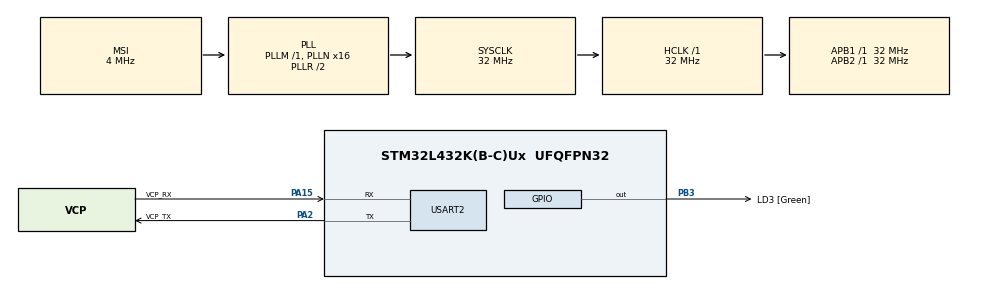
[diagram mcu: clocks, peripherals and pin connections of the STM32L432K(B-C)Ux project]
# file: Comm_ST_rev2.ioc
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Mcu.Family=STM32L4
Mcu.Name=STM32L432K(B-C)Ux
Mcu.Package=UFQFPN32
NVIC.PriorityGroup=NVIC_PRIORITYGROUP_4
NVIC.USART2_IRQn=true\:0\:0\:false\:false\:true
PA0.GPIO_Label=MCO [High speed clock in]
PA0.Signal=RCC_CK_IN
PA13\ (JTMS-SWDIO).GPIO_Label=SWDIO
PA13\ (JTMS-SWDIO).Signal=SYS_JTMS-SWDIO
PA14\ (JTCK-SWCLK).GPIO_Label=SWCLK
PA14\ (JTCK-SWCLK).Signal=SYS_JTCK-SWCLK
PA15\ (JTDI).GPIO_Label=VCP_RX
PA15\ (JTDI).Mode=Asynchronous
PA15\ (JTDI).Signal=USART2_RX
PA2.GPIO_Label=VCP_TX
PA2.Mode=Asynchronous
PA2.Signal=USART2_TX
PB3\ (JTDO-TRACESWO).GPIO_Label=LD3 [Green]
PB3\ (JTDO-TRACESWO).Signal=GPIO_Output
PC14-OSC32_IN\ (PC14).Signal=RCC_OSC32_IN
PC15-OSC32_OUT\ (PC15).Signal=RCC_OSC32_OUT
ProjectManager.HeapSize=0x200
ProjectManager.StackSize=0x400
ProjectManager.TargetToolchain=SW4STM32
RCC.AHBFreq_Value=32000000
RCC.APB1Freq_Value=32000000
RCC.APB1TimFreq_Value=32000000
RCC.APB2Freq_Value=32000000
RCC.APB2TimFreq_Value=32000000
RCC.CortexFreq_Value=32000000
RCC.HCLKFreq_Value=32000000
RCC.HSE_VALUE=8000000
RCC.HSI16_VALUE=16000000
RCC.HSI48_VALUE=48000000
RCC.HSI_VALUE=16000000
RCC.LSE_VALUE=32768
RCC.MSI_VALUE=4000000
RCC.PLLMUL=RCC_PLLMUL_4
RCC.PLLN=16
RCC.SYSCLKFreq_VALUE=32000000
RCC.SYSCLKSource=RCC_SYSCLKSOURCE_PLLCLK
RCC.VCOOutputFreq_Value=64000000
USART2.VirtualMode-Asynchronous=VM_ASYNC
USART2.WordLength=WORDLENGTH_8B
board=NUCLEO-L432KC

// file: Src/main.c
/**
  ******************************************************************************
  * File Name          : main.c
  * Description        : Main program body
  ******************************************************************************
  ** This notice applies to any and all portions of this file
  * that are not between comment pairs USER CODE BEGIN and
  * USER CODE END. Other portions of this file, whether
  * inserted by the user or by software development tools
  * are owned by their respective copyright owners.
  *
  * COPYRIGHT(c) 2018 STMicroelectronics
  *
  * Redistribution and use in source and binary forms, with or without modification,
  * are permitted provided that the following conditions are met:
  *   1. Redistributions of source code must retain the above copyright notice,
  *      this list of conditions and the following disclaimer.
  *   2. Redistributions in binary form must reproduce the above copyright notice,
  *      this list of conditions and the following disclaimer in the documentation
  *      and/or other materials provided with the distribution.
  *   3. Neither the name of STMicroelectronics nor the names of its contributors
  *      may be used to endorse or promote products derived from this software
  *      without specific prior written permission.
  *
  * THIS SOFTWARE IS PROVIDED BY THE COPYRIGHT HOLDERS AND CONTRIBUTORS "AS IS"
  * AND ANY EXPRESS OR IMPLIED WARRANTIES, INCLUDING, BUT NOT LIMITED TO, THE
  * IMPLIED WARRANTIES OF MERCHANTABILITY AND FITNESS FOR A PARTICULAR PURPOSE ARE
  * DISCLAIMED. IN NO EVENT SHALL THE COPYRIGHT HOLDER OR CONTRIBUTORS BE LIABLE
  * FOR ANY DIRECT, INDIRECT, INCIDENTAL, SPECIAL, EXEMPLARY, OR CONSEQUENTIAL
  * DAMAGES (INCLUDING, BUT NOT LIMITED TO, PROCUREMENT OF SUBSTITUTE GOODS OR
  * SERVICES; LOSS OF USE, DATA, OR PROFITS; OR BUSINESS INTERRUPTION) HOWEVER
  * CAUSED AND ON ANY THEORY OF LIABILITY, WHETHER IN CONTRACT, STRICT LIABILITY,
  * OR TORT (INCLUDING NEGLIGENCE OR OTHERWISE) ARISING IN ANY WAY OUT OF THE USE
  * OF THIS SOFTWARE, EVEN IF ADVISED OF THE POSSIBILITY OF SUCH DAMAGE.
  *
  ******************************************************************************
  */
#include "main.h"
#include "stm32l4xx_hal.h"
#include "usart.h"
#include "gpio.h"

/* USER CODE BEGIN Includes */
#include <string.h>
/* USER CODE END Includes */

/* USER CODE BEGIN PV */
/* Private variables ---------------------------------------------------------*/

/* USER CODE END PV */

void SystemClock_Config(void);

/* USER CODE BEGIN PFP */
/* Private function prototypes -----------------------------------------------*/

/* USER CODE END PFP */

/* USER CODE BEGIN 0 */

typedef struct __attribute__((packed, aligned(1))) RobotStatus{
	uint32_t id;
	char	msg[12];
} RobotStatus;
//typedef struct __attribute__((packed, aligned(1))) RobotStatus{

// } RobotStatus;
RobotStatus RS;
// scratch buffer
uint8_t Rx_char = 0;
uint8_t	Rx_index = 0;
uint8_t	is_prev_esc = 0;
uint8_t	has_started = 0;

#define MAX_SIZE_MSG sizeof(RobotStatus)
uint8_t Rx_msg[MAX_SIZE_MSG];

#define ESCAPE	0xFF
#define ESC_START	0x0F
#define ESC_END		0xF0
#define START	0x55
#define END		0xAA
// RXCallback
void RX_Parser(){
	switch(Rx_char){
		case START:	Rx_index = 0;
				is_prev_esc = 0;
				has_started = 1;
				break;
		case END:	// validate
				if(Rx_index == MAX_SIZE_MSG){
					memcpy(&RS, Rx_msg, (uint32_t)sizeof(RobotStatus));
					// Tx_Parser(&RS, sizeof(RobotStatus));
					// HAL_UART_Transmit_IT(&huart2, &RS, sizeof(RobotStatus));
				}
				is_prev_esc = 0;
				has_started = 0;
				Rx_index = 0;
				break;
		// ESCAPE
		// ESCAPE then ESCAPE
		case ESCAPE:	if(has_started){	// ignore out of context data
					if(is_prev_esc){
						Rx_msg[Rx_index] = ESCAPE;
						is_prev_esc = 0;
						Rx_index++;
					}
					else{
						is_prev_esc = 1;
					}
				}
				break;
		// ESCAPE then ESC_START
		case ESC_START:	if(has_started){
							Rx_msg[Rx_index] = (is_prev_esc) ? START : ESC_START;
							is_prev_esc = 0;
							Rx_index++;
						}
				break;
		// ESCAPE then ESC_START
		case ESC_END:	if(has_started){
							Rx_msg[Rx_index] = (is_prev_esc) ? END : ESC_END;
							is_prev_esc = 0;
							Rx_index++;
						}
				break;
		default:
				if(has_started && (is_prev_esc == 0)){
					Rx_msg[Rx_index] = Rx_char;
					Rx_index++;
					is_prev_esc = 0;
				}
	}
	HAL_UART_Receive_IT(&huart2, &Rx_char, 1);
}

#define UART_HANDLER &huart2
static void send_byte(uint8_t byte) {
	// Encapsulates the data into a packet
#ifdef PC
	int wlen = write(fd, &byte, 1);
	if (wlen != 1) {
		printf("Error from write: %d, %d\n", wlen, errno);
	}
	tcflush(fd, TCOFLUSH);
#else
	HAL_UART_Transmit(UART_HANDLER, &byte, 1, 1);
#endif
}

void Tx_Parser(uint8_t* addr, uint16_t size){
	send_byte(START);
	for(uint16_t i = 0; i < size; i++){
		switch(addr[i]){
			case START:
				send_byte(ESCAPE);
				send_byte(ESC_START);
				break;
			case END:
				send_byte(ESCAPE);
				send_byte(ESC_END);
				break;
			case ESCAPE:
				send_byte(ESCAPE);
				send_byte(ESCAPE);
				break;
			default:
				send_byte(addr[i]);
		}
	}
	send_byte(END);
}
/* USER CODE END 0 */

int main(void)
{

  /* MCU Configuration----------------------------------------------------------*/

  /* Reset of all peripherals, Initializes the Flash interface and the Systick. */
  HAL_Init();

  /* Configure the system clock */
  SystemClock_Config();

  /* Initialize all configured peripherals */
  MX_GPIO_Init();
  MX_USART2_UART_Init();

  /* USER CODE BEGIN 2 */
  HAL_UART_Receive_IT(&huart2, &Rx_char, 1);
  //RS.id = 3;
  //memcpy(RS.msg, "Test12345!@#", 12);
  //Tx_Parser(&RS, sizeof(RobotStatus));
  /* USER CODE END 2 */

  /* Infinite loop */
  while (1)
  {

  }

}

/** System Clock Configuration
*/
void SystemClock_Config(void)
{

  RCC_OscInitTypeDef RCC_OscInitStruct;
  RCC_ClkInitTypeDef RCC_ClkInitStruct;
  RCC_PeriphCLKInitTypeDef PeriphClkInit;

    /**Initializes the CPU, AHB and APB busses clocks
    */
  RCC_OscInitStruct.OscillatorType = RCC_OSCILLATORTYPE_MSI;
  RCC_OscInitStruct.MSIState = RCC_MSI_ON;
  RCC_OscInitStruct.MSICalibrationValue = 0;
  RCC_OscInitStruct.MSIClockRange = RCC_MSIRANGE_6;
  RCC_OscInitStruct.PLL.PLLState = RCC_PLL_ON;
  RCC_OscInitStruct.PLL.PLLSource = RCC_PLLSOURCE_MSI;
  RCC_OscInitStruct.PLL.PLLM = 1;
  RCC_OscInitStruct.PLL.PLLN = 16;
  RCC_OscInitStruct.PLL.PLLP = RCC_PLLP_DIV7;
  RCC_OscInitStruct.PLL.PLLQ = RCC_PLLQ_DIV2;
  RCC_OscInitStruct.PLL.PLLR = RCC_PLLR_DIV2;
  if (HAL_RCC_OscConfig(&RCC_OscInitStruct) != HAL_OK)
  {
    _Error_Handler(__FILE__, __LINE__);
  }

    /**Initializes the CPU, AHB and APB busses clocks
    */
  RCC_ClkInitStruct.ClockType = RCC_CLOCKTYPE_HCLK|RCC_CLOCKTYPE_SYSCLK
                              |RCC_CLOCKTYPE_PCLK1|RCC_CLOCKTYPE_PCLK2;
  RCC_ClkInitStruct.SYSCLKSource = RCC_SYSCLKSOURCE_PLLCLK;
  RCC_ClkInitStruct.AHBCLKDivider = RCC_SYSCLK_DIV1;
  RCC_ClkInitStruct.APB1CLKDivider = RCC_HCLK_DIV1;
  RCC_ClkInitStruct.APB2CLKDivider = RCC_HCLK_DIV1;

  if (HAL_RCC_ClockConfig(&RCC_ClkInitStruct, FLASH_LATENCY_1) != HAL_OK)
  {
    _Error_Handler(__FILE__, __LINE__);
  }

  PeriphClkInit.PeriphClockSelection = RCC_PERIPHCLK_USART2;
  PeriphClkInit.Usart2ClockSelection = RCC_USART2CLKSOURCE_PCLK1;
  if (HAL_RCCEx_PeriphCLKConfig(&PeriphClkInit) != HAL_OK)
  {
    _Error_Handler(__FILE__, __LINE__);
  }

    /**Configure the main internal regulator output voltage
    */
  if (HAL_PWREx_ControlVoltageScaling(PWR_REGULATOR_VOLTAGE_SCALE1) != HAL_OK)
  {
    _Error_Handler(__FILE__, __LINE__);
  }

    /**Configure the Systick interrupt time
    */
  HAL_SYSTICK_Config(HAL_RCC_GetHCLKFreq()/1000);

    /**Configure the Systick
    */
  HAL_SYSTICK_CLKSourceConfig(SYSTICK_CLKSOURCE_HCLK);

  /* SysTick_IRQn interrupt configuration */
  HAL_NVIC_SetPriority(SysTick_IRQn, 0, 0);
}

/* USER CODE BEGIN 4 */
void HAL_UART_RxCpltCallback(UART_HandleTypeDef * huart) {
	if (huart == &huart2) {
		RX_Parser();
	}

}
/* USER CODE END 4 */

void _Error_Handler(char * file, int line)
{
  while(1)
  {
  }
}

/************************ (C) COPYRIGHT STMicroelectronics *****END OF FILE****/
